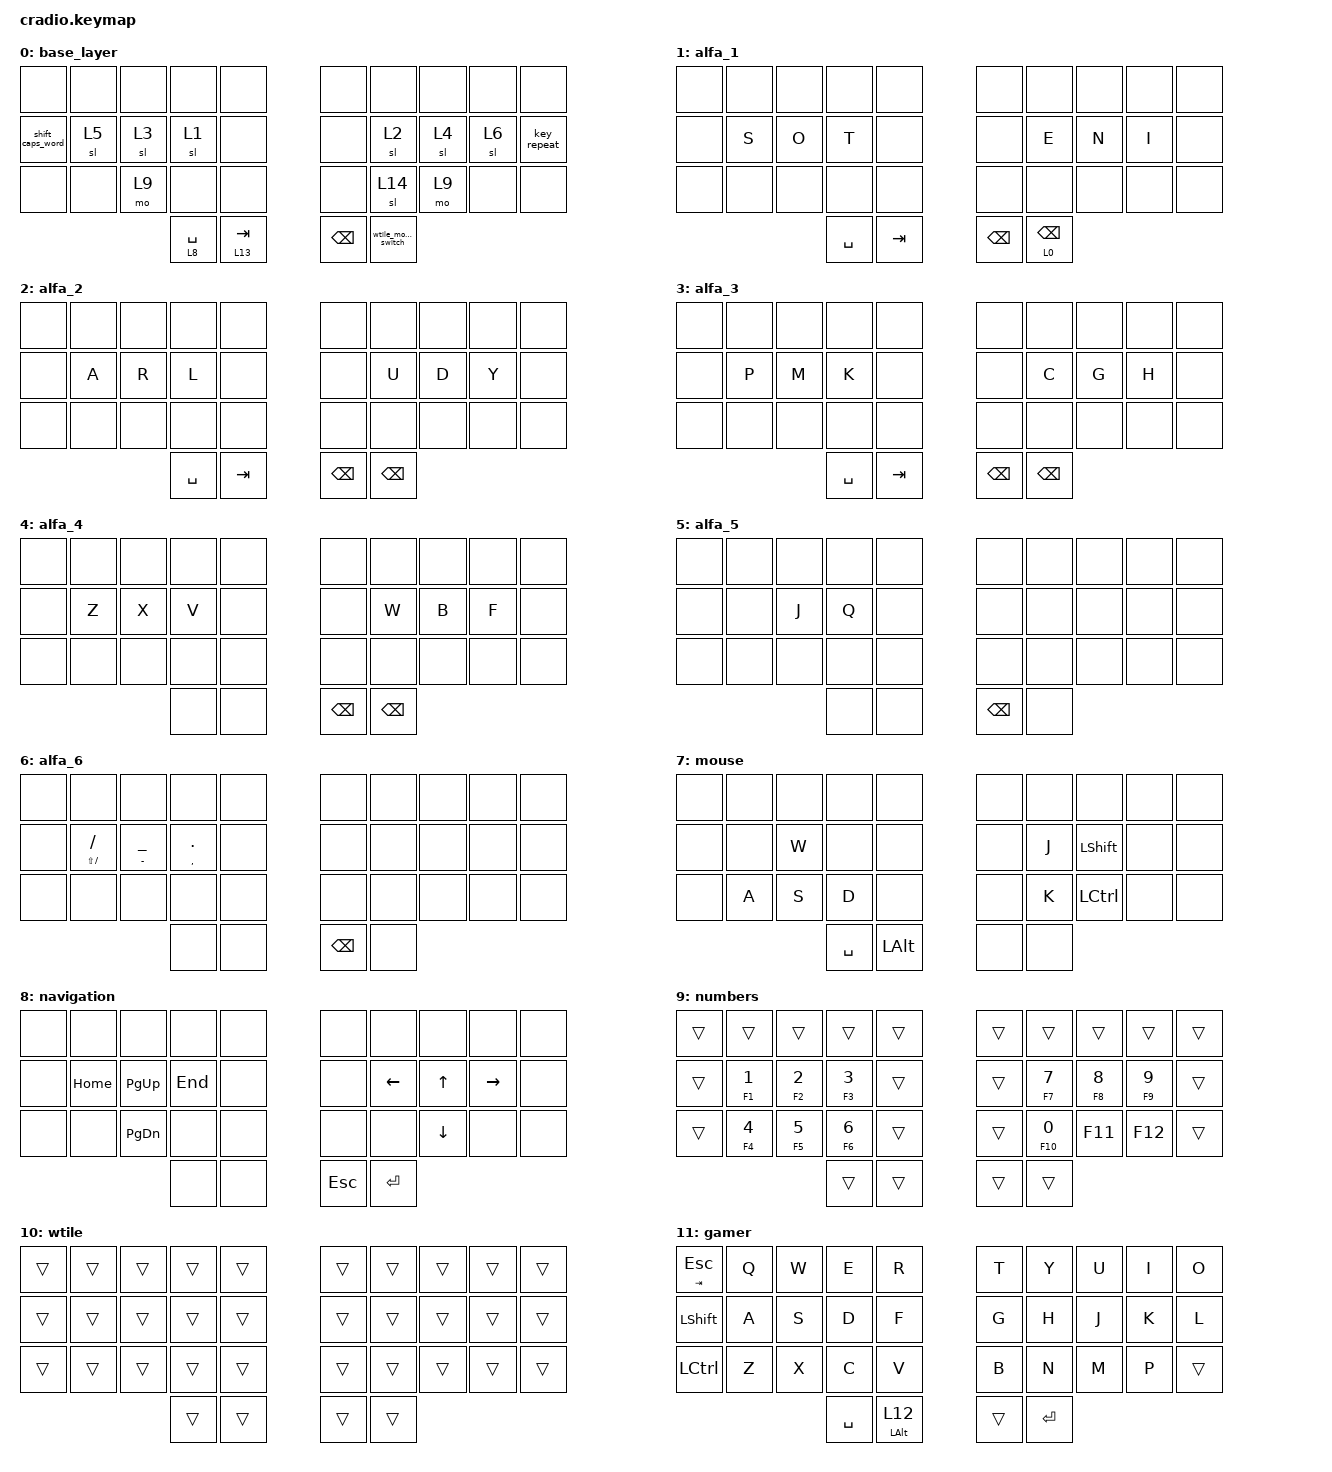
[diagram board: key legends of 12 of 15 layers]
// Copyright (c) 2022 The ZMK Contributors
// SPDX-License-Identifier: MIT

#include <behaviors.dtsi>
#include <dt-bindings/zmk/keys.h>

// Home row mods macro

&sl { release-after-ms = <500>; };

/ {
    behaviors {
        ht: hold_tap {
            compatible = "zmk,behavior-hold-tap";
            #binding-cells = <2>;
            flavor = "tap-preferred";
            tapping-term-ms = <220>;
            quick-tap-ms = <150>;
            require-prior-idle-ms = <100>;
            bindings = <&kp>, <&kp>;
        };

        shift_caps_word: shift_caps_word {
            compatible = "zmk,behavior-tap-dance";
            label = "SHIFT_CAPS_WORD";
            #binding-cells = <0>;
            bindings = <&sk LSHFT>, <&caps_word>;
        };

        mod_sk: mod_sk {
            compatible = "zmk,behavior-hold-tap";
            label = "MOD_SK";
            bindings = <&mo>, <&sk>;

            #binding-cells = <2>;
            flavor = "tap-preferred";
            tapping-term-ms = <200>;
        };

        kp_sl: kp_sl {
            compatible = "zmk,behavior-hold-tap";
            label = "KP_SL";
            bindings = <&kp>, <&sl>;

            #binding-cells = <2>;
            tapping-term-ms = <150>;
            flavor = "tap-preferred";
        };

        mo_kp: mo_kp {
            compatible = "zmk,behavior-hold-tap";
            label = "MO_KP";
            bindings = <&mo>, <&kp>;

            #binding-cells = <2>;
            flavor = "tap-preferred";
            tapping-term-ms = <200>;
        };

        kp_sk: kp_sk {
            compatible = "zmk,behavior-hold-tap";
            label = "KP_SK";
            bindings = <&kp>, <&sk>;

            #binding-cells = <2>;
            tapping-term-ms = <200>;
        };

        Test: Test {
            compatible = "zmk,behavior-sticky-key";
            label = "TEST";
            bindings = <&kp>;
            #binding-cells = <1>;
            release-after-ms = <300>;
            ignore-modifiers;
            quick-release;
        };
    };

    conditional_layers { compatible = "zmk,conditional-layers"; };

    macros {
        wtile_mouse_switch: wtile_switch {
            compatible = "zmk,behavior-macro";
            #binding-cells = <0>;
            bindings =
                <&macro_press>,
                <&mo 7 &kp SEMI>,
                <&macro_pause_for_release>,
                <&macro_release>,
                <&kp SEMI &mo 7>;

            label = "WTILE_SWITCH";
        };
    };

    combos {
        compatible = "zmk,combos";

        bootloader {
            bindings = <&bootloader>;
            key-positions = <10 11 12 13>;
            layers = <0>;
        };

        to_gamer {
            bindings = <&tog 11>;
            key-positions = <16 17 18 19>;
            layers = <0 11>;
        };
    };

    keymap {
        compatible = "zmk,keymap";

        base_layer {
            bindings = <
&none             &none  &none  &none        &none            &none          &none                &none  &none  &none
&shift_caps_word  &sl 5  &sl 3  &sl 1        &none            &none          &sl 2                &sl 4  &sl 6  &key_repeat
&none             &none  &mo 9  &none        &none            &none          &sl 14               &mo 9  &none  &none
                                &lt 8 SPACE  &mo_kp 13 TAB    &kp BACKSPACE  &wtile_mouse_switch
            >;
        };

        alfa_1 {
            bindings = <
&none  &none  &none  &none      &none      &none     &none       &none  &none  &none
&none  &kp S  &kp O  &kp T      &none      &none     &kp E       &kp N  &kp I  &none
&none  &none  &none  &none      &none      &none     &none       &none  &none  &none
                     &kp SPACE  &kp TAB    &kp BSPC  &lt 0 BSPC
            >;
        };

        alfa_2 {
            bindings = <
&none  &none  &none  &none      &none      &none     &none     &none  &none  &none
&none  &kp A  &kp R  &kp L      &none      &none     &kp U     &kp D  &kp Y  &none
&none  &none  &none  &none      &none      &none     &none     &none  &none  &none
                     &kp SPACE  &kp TAB    &kp BSPC  &kp BSPC
            >;
        };

        alfa_3 {
            bindings = <
&none  &none  &none  &none      &none      &none     &none     &none  &none  &none
&none  &kp P  &kp M  &kp K      &none      &none     &kp C     &kp G  &kp H  &none
&none  &none  &none  &none      &none      &none     &none     &none  &none  &none
                     &kp SPACE  &kp TAB    &kp BSPC  &kp BSPC
            >;
        };

        alfa_4 {
            bindings = <
&none  &none  &none  &none  &none    &none     &none     &none  &none  &none
&none  &kp Z  &kp X  &kp V  &none    &none     &kp W     &kp B  &kp F  &none
&none  &none  &none  &none  &none    &none     &none     &none  &none  &none
                     &none  &none    &kp BSPC  &kp BSPC
            >;
        };

        alfa_5 {
            bindings = <
&none  &none  &none  &none  &none    &none     &none  &none  &none  &none
&none  &none  &kp J  &kp Q  &none    &none     &none  &none  &none  &none
&none  &none  &none  &none  &none    &none     &none  &none  &none  &none
                     &none  &none    &kp BSPC  &none
            >;
        };

        alfa_6 {
            bindings = <
&none  &none              &none            &none          &none    &none     &none  &none  &none  &none
&none  &ht LS(FSLH) FSLH  &ht MINUS UNDER  &ht COMMA DOT  &none    &none     &none  &none  &none  &none
&none  &none              &none            &none          &none    &none     &none  &none  &none  &none
                                           &none          &none    &kp BSPC  &none
            >;
        };

        mouse {
            bindings = <
&none  &none  &none  &none      &none       &none  &none  &none      &none  &none
&none  &none  &kp W  &none      &none       &none  &kp J  &kp LSHFT  &none  &none
&none  &kp A  &kp S  &kp D      &none       &none  &kp K  &kp LCTRL  &none  &none
                     &kp SPACE  &kp LALT    &none  &none
            >;
        };

        navigation {
            bindings = <
&none  &none     &none          &none    &none    &none       &none      &none     &none      &none
&none  &kp HOME  &kp PAGE_UP    &kp END  &none    &none       &kp LEFT   &kp UP    &kp RIGHT  &none
&none  &none     &kp PAGE_DOWN  &none    &none    &none       &none      &kp DOWN  &none      &none
                                &none    &none    &kp ESCAPE  &kp ENTER
            >;
        };

        numbers {
            bindings = <
&trans  &trans           &trans           &trans           &trans    &trans  &trans      &trans     &trans     &trans
&trans  &ht F1 NUMBER_1  &ht F2 NUMBER_2  &ht F3 NUMBER_3  &trans    &trans  &ht F7 N7   &ht F8 N8  &ht F9 N9  &trans
&trans  &ht F4 NUMBER_4  &ht F5 N5        &ht F6 NUMBER_6  &trans    &trans  &ht F10 N0  &kp F11    &kp F12    &trans
                                          &trans           &trans    &trans  &trans
            >;
        };

        wtile {
            bindings = <
&trans  &trans  &trans  &trans  &trans    &trans  &trans  &trans  &trans  &trans
&trans  &trans  &trans  &trans  &trans    &trans  &trans  &trans  &trans  &trans
&trans  &trans  &trans  &trans  &trans    &trans  &trans  &trans  &trans  &trans
                        &trans  &trans    &trans  &trans
            >;
        };

        gamer {
            bindings = <
&ht TAB ESCAPE  &kp Q  &kp W  &kp E      &kp R                 &kp T   &kp Y      &kp U  &kp I  &kp O
&kp LSHFT       &kp A  &kp S  &kp D      &kp F                 &kp G   &kp H      &kp J  &kp K  &kp L
&kp LCTRL       &kp Z  &kp X  &kp C      &kp V                 &kp B   &kp N      &kp M  &kp P  &trans
                              &kp SPACE  &kp_sl LEFT_ALT 12    &trans  &kp ENTER
            >;
        };

        gamer_alt {
            bindings = <
&kp T  &kp Y  &kp U  &kp I   &kp O     &trans  &trans  &trans  &trans  &trans
&kp G  &kp H  &kp J  &kp K   &kp L     &trans  &trans  &trans  &trans  &trans
&kp B  &kp N  &kp M  &kp P   &trans    &trans  &trans  &trans  &trans  &trans
                     &trans  &trans    &trans  &trans
            >;
        };

        symbol {
            bindings = <
&none  &none  &none  &none              &none    &none  &none  &none  &none  &none
&none  &none  &none  &ht LS(N9) LS(N8)  &none    &none  &none  &none  &none  &none
&none  &none  &none  &none              &none    &none  &none  &none  &none  &none
                     &none              &none    &none  &none
            >;
        };

        mod {
            bindings = <
&trans            &trans        &trans     &trans     &trans    &trans  &trans            &trans             &trans           &trans
&kp_sk LWIN LWIN  &none         &none      &none      &trans    &trans  &kp C_MUTE        &kp C_VOLUME_DOWN  &kp C_VOLUME_UP  &trans
&trans            &sk LEFT_ALT  &sk LSHFT  &sk LCTRL  &trans    &trans  &kp C_PLAY_PAUSE  &kp C_PREV         &kp C_NEXT       &trans
                                           &trans     &trans    &trans  &trans
            >;
        };
    };
};
